AUTOSAR XML (schema 4-3-0)
standard types defined: uint8, uint8_DataConstr
package /ComponentTypes
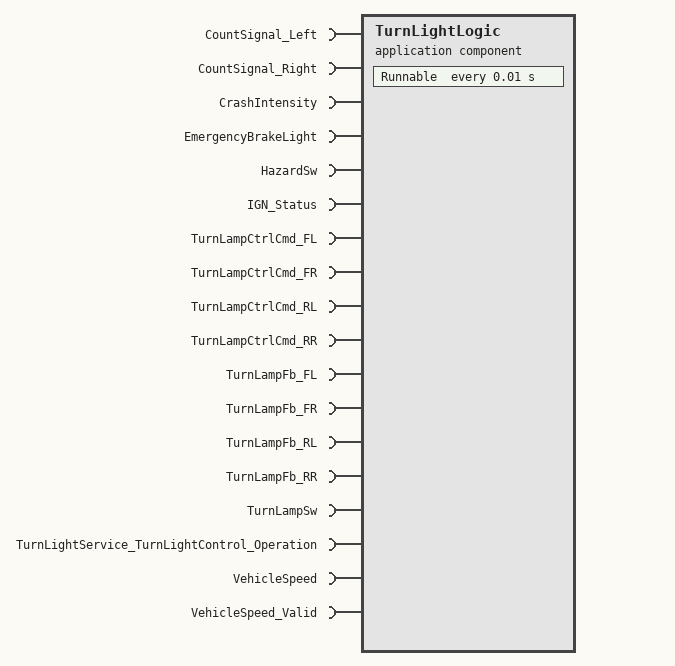
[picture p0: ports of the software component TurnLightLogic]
  application sw component type TurnLightLogic
    18 x require port:
      CountSignal_Left: nonqueued-receiver-com-spec{data-element=CountSignal_Left/Signal, filter=data-filter-type=ALWAYS, init-value=0}, required-interface=CountSignal_Left
      CountSignal_Right: nonqueued-receiver-com-spec{data-element=CountSignal_Right/Signal, filter=data-filter-type=ALWAYS, init-value=0}, required-interface=CountSignal_Right
      CrashIntensity: nonqueued-receiver-com-spec{data-element=CrashIntensity/Signal, filter=data-filter-type=ALWAYS, init-value=0}, required-interface=CrashIntensity
      EmergencyBrakeLight: nonqueued-receiver-com-spec{data-element=EmergencyBrakeLight/Signal, filter=data-filter-type=ALWAYS, init-value=0}, required-interface=EmergencyBrakeLight
      HazardSw: nonqueued-receiver-com-spec{data-element=HazardSw/Signal, filter=data-filter-type=ALWAYS, init-value=0}, required-interface=HazardSw
      IGN_Status: nonqueued-receiver-com-spec{data-element=IGN_Status/Signal, filter=data-filter-type=ALWAYS, init-value=0}, required-interface=IGN_Status
      TurnLampCtrlCmd_FL: nonqueued-receiver-com-spec{data-element=TurnLampCtrlCmd_FL/Signal, filter=data-filter-type=ALWAYS, init-value=0}, required-interface=TurnLampCtrlCmd_FL
      TurnLampCtrlCmd_FR: nonqueued-receiver-com-spec{data-element=TurnLampCtrlCmd_FR/Signal, filter=data-filter-type=ALWAYS, init-value=0}, required-interface=TurnLampCtrlCmd_FR
      TurnLampCtrlCmd_RL: nonqueued-receiver-com-spec{data-element=TurnLampCtrlCmd_RL/Signal, filter=data-filter-type=ALWAYS, init-value=0}, required-interface=TurnLampCtrlCmd_RL
      TurnLampCtrlCmd_RR: nonqueued-receiver-com-spec{data-element=TurnLampCtrlCmd_RR/Signal, filter=data-filter-type=ALWAYS, init-value=0}, required-interface=TurnLampCtrlCmd_RR
      TurnLampFb_FL: nonqueued-receiver-com-spec{data-element=TurnLampFb_FL/Signal, filter=data-filter-type=ALWAYS, init-value=0}, required-interface=TurnLampFb_FL
      TurnLampFb_FR: nonqueued-receiver-com-spec{data-element=TurnLampFb_FR/Signal, filter=data-filter-type=ALWAYS, init-value=0}, required-interface=TurnLampFb_FR
      TurnLampFb_RL: nonqueued-receiver-com-spec{data-element=TurnLampFb_RL/Signal, filter=data-filter-type=ALWAYS, init-value=0}, required-interface=TurnLampFb_RL
      TurnLampFb_RR: nonqueued-receiver-com-spec{data-element=TurnLampFb_RR/Signal, filter=data-filter-type=ALWAYS, init-value=0}, required-interface=TurnLampFb_RR
      TurnLampSw: nonqueued-receiver-com-spec{data-element=TurnLampSw/Signal, filter=data-filter-type=ALWAYS, init-value=0}, required-interface=TurnLampSw
      TurnLightService_TurnLightControl_Operation: client-com-spec=Operation, required-interface=TurnLightService_TurnLightControl_Operation
      VehicleSpeed: nonqueued-receiver-com-spec{data-element=VehicleSpeed/Signal, filter=data-filter-type=ALWAYS, init-value=0}, required-interface=VehicleSpeed
      VehicleSpeed_Valid: nonqueued-receiver-com-spec{data-element=VehicleSpeed_Valid/Signal, filter=data-filter-type=ALWAYS, init-value=0}, required-interface=VehicleSpeed_Valid
    behavior TurnLightLogic_InternalBehavior
      timing event TMT_Runnable: start-on-event=Runnable, period=0.01
      runnable Runnable: minimum-start-interval=0.01
        data-receive-point-by-arguments:
          17 x access:
            REC_CountSignal_Left_Signal: accessed-variable=CountSignal_Left.Signal
            REC_CountSignal_Right_Signal: accessed-variable=CountSignal_Right.Signal
            REC_CrashIntensity_Signal: accessed-variable=CrashIntensity.Signal
            REC_EmergencyBrakeLight_Signal: accessed-variable=EmergencyBrakeLight.Signal
            REC_HazardSw_Signal: accessed-variable=HazardSw.Signal
            REC_IGN_Status_Signal: accessed-variable=IGN_Status.Signal
            REC_TurnLampCtrlCmd_FL_Signal: accessed-variable=TurnLampCtrlCmd_FL.Signal
            REC_TurnLampCtrlCmd_FR_Signal: accessed-variable=TurnLampCtrlCmd_FR.Signal
            REC_TurnLampCtrlCmd_RL_Signal: accessed-variable=TurnLampCtrlCmd_RL.Signal
            REC_TurnLampCtrlCmd_RR_Signal: accessed-variable=TurnLampCtrlCmd_RR.Signal
            REC_TurnLampFb_FL_Signal: accessed-variable=TurnLampFb_FL.Signal
            REC_TurnLampFb_FR_Signal: accessed-variable=TurnLampFb_FR.Signal
            REC_TurnLampFb_RL_Signal: accessed-variable=TurnLampFb_RL.Signal
            REC_TurnLampFb_RR_Signal: accessed-variable=TurnLampFb_RR.Signal
            REC_TurnLampSw_Signal: accessed-variable=TurnLampSw.Signal
            REC_VehicleSpeed_Signal: accessed-variable=VehicleSpeed.Signal
            REC_VehicleSpeed_Valid_Signal: accessed-variable=VehicleSpeed_Valid.Signal
        sync call SC_TurnLightService_TurnLightControl_Operation_Operation: operation=TurnLightService_TurnLightControl_Operation.Operation, timeout=0
  swc implementation TurnLightLogic_Implementation: behavior=TurnLightLogic_InternalBehavior
    code-descriptors:
      code Default: artifact-descriptors=autosar-engineering-object={short-label=Default, category=SWSRC}
package /DataTypes
  impl type TurnLightService_Ctrl_Oeration: category=STRUCTURE, sw-calibration-access=READ-WRITE, type-emitter=RTE
    7 x element, all with category=TYPE_REFERENCE, implementation-data-type=uint8:
      TurnLightPosition: compu {0=NOREQUEST, 1=LEFT, 2=RIGHT, 3=ALL, 4=FRONT_LEFT, 5=MIDDLE_LEFT, 6=REAR_LEFT, 7=FRONT_RIGHT, 8=MIDDLE_RIGHT, 9=REAR_RIGHT, else 0}, invalid-value=0
      TurnLightOnOff: compu {0=NOREQUEST, 1=OFF, 2=ON}, invalid-value=0
      TurnLightDutyCycle: invalid-value=0
      TurnLightCycle
      TurnLightTimes: invalid-value=0
      TurnLightNum
      TurnLightPriority
package /PortInterfaces
  client server interface TurnLightService_TurnLightControl_Operation
    operation Operation
      arg TurnLightCtrlPara: sw-calibration-access=READ-WRITE, type=TurnLightService_Ctrl_Oeration, direction=IN, server-argument-impl-policy=USE-ARGUMENT-TYPE
  17 x sender receiver interface:
    CountSignal_Left: invalidation-policy{data-element=CountSignal_Left/Signal, handle-invalid=DONT-INVALIDATE}
      data Signal: type=uint8
    CountSignal_Right: invalidation-policy{data-element=CountSignal_Right/Signal, handle-invalid=DONT-INVALIDATE}
      data Signal: type=uint8
    CrashIntensity: invalidation-policy{data-element=CrashIntensity/Signal, handle-invalid=DONT-INVALIDATE}
      data Signal: type=uint8
    EmergencyBrakeLight: invalidation-policy{data-element=EmergencyBrakeLight/Signal, handle-invalid=DONT-INVALIDATE}
      data Signal: type=uint8
    HazardSw: invalidation-policy{data-element=HazardSw/Signal, handle-invalid=DONT-INVALIDATE}
      data Signal: type=uint8
    IGN_Status: invalidation-policy{data-element=IGN_Status/Signal, handle-invalid=DONT-INVALIDATE}
      data Signal: type=uint8
    TurnLampCtrlCmd_FL: invalidation-policy{data-element=TurnLampCtrlCmd_FL/Signal, handle-invalid=DONT-INVALIDATE}
      data Signal: type=uint8
    TurnLampCtrlCmd_FR: invalidation-policy{data-element=TurnLampCtrlCmd_FR/Signal, handle-invalid=DONT-INVALIDATE}
      data Signal: type=uint8
    TurnLampCtrlCmd_RL: invalidation-policy{data-element=TurnLampCtrlCmd_RL/Signal, handle-invalid=DONT-INVALIDATE}
      data Signal: type=uint8
    TurnLampCtrlCmd_RR: invalidation-policy{data-element=TurnLampCtrlCmd_RR/Signal, handle-invalid=DONT-INVALIDATE}
      data Signal: type=uint8
    TurnLampFb_FL: invalidation-policy{data-element=TurnLampFb_FL/Signal, handle-invalid=DONT-INVALIDATE}
      data Signal: type=uint8
    TurnLampFb_FR: invalidation-policy{data-element=TurnLampFb_FR/Signal, handle-invalid=DONT-INVALIDATE}
      data Signal: type=uint8
    TurnLampFb_RL: invalidation-policy{data-element=TurnLampFb_RL/Signal, handle-invalid=DONT-INVALIDATE}
      data Signal: type=uint8
    TurnLampFb_RR: invalidation-policy{data-element=TurnLampFb_RR/Signal, handle-invalid=DONT-INVALIDATE}
      data Signal: type=uint8
    TurnLampSw: invalidation-policy{data-element=TurnLampSw/Signal, handle-invalid=DONT-INVALIDATE}
      data Signal: type=uint8
    VehicleSpeed: invalidation-policy{data-element=VehicleSpeed/Signal, handle-invalid=DONT-INVALIDATE}
      data Signal: type=uint8
    VehicleSpeed_Valid: invalidation-policy{data-element=VehicleSpeed_Valid/Signal, handle-invalid=DONT-INVALIDATE}
      data Signal: type=uint8
